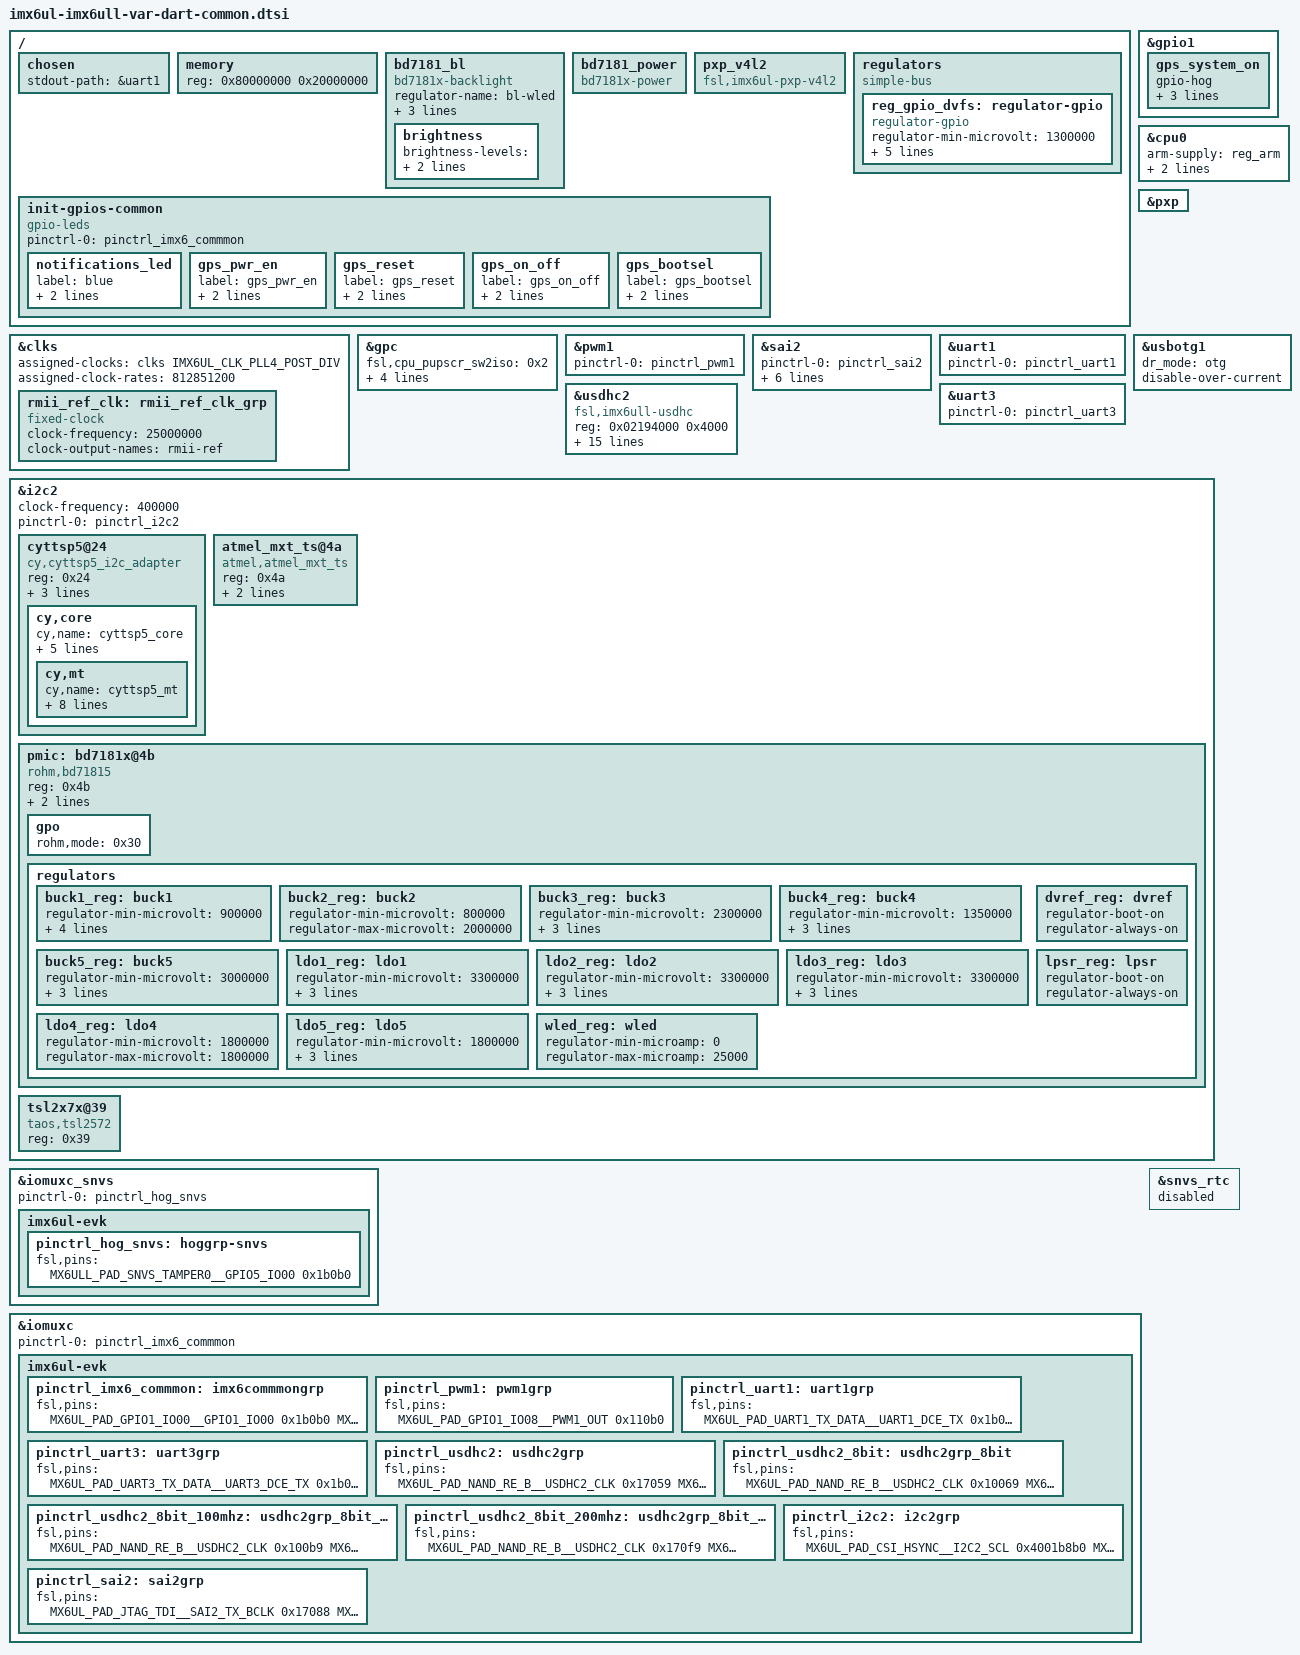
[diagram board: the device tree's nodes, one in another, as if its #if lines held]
/*
 * Copyright (C) 2015 Freescale Semiconductor, Inc.
 *
 * Copyright (C) 2015-2017 Variscite Ltd. - http://www.variscite.com
 *
 * This program is free software; you can redistribute it and/or modify
 * it under the terms of the GNU General Public License version 2 as
 * published by the Free Software Foundation.
 */
/* #define WIFI */
/* #define EMMC */
/* #define  NAND  */
 
/ {
	chosen {
		stdout-path = &uart1;
	};

	memory {
		reg = <0x80000000 0x20000000>;
	};

	bd7181_bl {
		compatible = "bd7181x-backlight";
		regulator-name = "bl-wled";
		regulator-boot-on;
		regulator-supply = "backlight";
		backlight-supply = <&wled_reg>;

		brightness {
			brightness-levels = <0 10 20 30 50 70 100 200 300 500 700 1000 2000 3000 4000 5000 6000 7000 8000 9000 
								10000 11000 12000 13000 14000 15000 16000 17000 18000 19000 20000 21000 22000 23000 24000 25000>;
			default-brightness-level = <15>;
		};
	};

	bd7181_power {
		compatible = "bd7181x-power";
		status = "okay";
	};

	pxp_v4l2 {
		compatible = "fsl,imx6ul-pxp-v4l2", "fsl,imx6sx-pxp-v4l2", "fsl,imx6sl-pxp-v4l2";
		status = "okay";
	};

	
	regulators {
		compatible = "simple-bus";
		#address-cells = <1>;
		#size-cells = <0>;
		
		reg_gpio_dvfs: regulator-gpio {
			compatible = "regulator-gpio";
			regulator-min-microvolt = <1300000>;
			regulator-max-microvolt = <1400000>;
			regulator-name = "gpio_dvfs";
			regulator-type = "voltage";
			gpios = <&gpio4 13 GPIO_ACTIVE_HIGH>;
			states = <1300000 0x1 1400000 0x0>;
		};
	};

	init-gpios-common {
		compatible = "gpio-leds";
		pinctrl-names = "default";
		pinctrl-0 = <&pinctrl_imx6_commmon>;

		notifications_led {
			label = "blue";
			gpios = <&gpio1 7 GPIO_ACTIVE_HIGH>;
			default-state = "off";
		};

		gps_pwr_en {
			label = "gps_pwr_en";
			gpios = <&gpio2 3 GPIO_ACTIVE_HIGH>;
			default-state = "off";
		};

		gps_reset {
			label = "gps_reset";
			gpios = <&gpio1 18 GPIO_ACTIVE_HIGH>;
			default-state = "off";
		};

		gps_on_off {
			label = "gps_on_off";
			gpios = <&gpio1 26 GPIO_ACTIVE_HIGH>;
			default-state = "off";
		};

		gps_bootsel {
			label = "gps_bootsel";
			gpios = <&gpio1 19 GPIO_ACTIVE_HIGH>;
			default-state = "off";
		};

	};

};

&gpio1 {
	gps_system_on {
		gpio-hog;
        gpios = <27 GPIO_ACTIVE_LOW>;
        input;
        line-name = "gps_system_on";
	};
};

&cpu0 {
	arm-supply = <&reg_arm>;
	soc-supply = <&reg_soc>;
	dc-supply = <&reg_gpio_dvfs>;
};

&clks {
	/* ref_clk for micrel ethernet phy */
	rmii_ref_clk: rmii_ref_clk_grp {
		compatible = "fixed-clock";
		#clock-cells = <0>;
		clock-frequency = <25000000>;
		clock-output-names = "rmii-ref";
	};
};

&clks {
	assigned-clocks = <&clks IMX6UL_CLK_PLL4_POST_DIV>;
	assigned-clock-rates = <812851200>;
};

&gpc {
	fsl,cpu_pupscr_sw2iso = <0x2>;
	fsl,cpu_pupscr_sw = <0x1>;
	fsl,cpu_pdnscr_iso2sw = <0x1>;
	fsl,cpu_pdnscr_iso = <0x1>;
	fsl,ldo-bypass = <0>; /* DCDC, ldo-enable */
};

&pwm1 {
	pinctrl-names = "default";
	pinctrl-0 = <&pinctrl_pwm1>;
	status = "okay";
};

&pxp {
	status = "okay";
};

&sai2 {
	pinctrl-names = "default";
	pinctrl-0 = <&pinctrl_sai2>;
	assigned-clocks = <&clks IMX6UL_CLK_SAI2_SEL>,
                      <&clks IMX6UL_CLK_PLL4_AUDIO_DIV>,
                      <&clks IMX6UL_CLK_SAI2>;
	assigned-clock-rates = <0>, <786432000>, <12288000>;
	assigned-clock-parents = <&clks IMX6UL_CLK_PLL4_AUDIO_DIV>;
	status = "okay";
};

/* Console UART */
&uart1 {
	pinctrl-names = "default";
	pinctrl-0 = <&pinctrl_uart1>;
	status = "okay";
};

/* ttymxc2 UART [GPS]*/
&uart3 {
	pinctrl-names = "default";
	pinctrl-0 = <&pinctrl_uart3>;
	status = "okay";
};

&usbotg1 {
	dr_mode = "otg";
	disable-over-current;
	status = "okay";
};

&usdhc2 {
	compatible = "fsl,imx6ull-usdhc", "fsl,imx6sx-usdhc";
	reg = <0x02194000 0x4000>;
	interrupts = <GIC_SPI 23 IRQ_TYPE_LEVEL_HIGH>;
	clocks = <&clks IMX6UL_CLK_USDHC2>,
		 <&clks IMX6UL_CLK_USDHC2>,
		 <&clks IMX6UL_CLK_USDHC2>;
	clock-names = "ipg", "ahb", "per";
	assigned-clocks = <&clks IMX6UL_CLK_USDHC2_SEL>, <&clks IMX6UL_CLK_USDHC2>;
	assigned-clock-parents = <&clks IMX6UL_CLK_PLL2_PFD2>;
	assigned-clock-rates = <0>, <132000000>;
	bus-width = <8>;
	fsl,tuning-step= <2>;
	pinctrl-names = "default", "state_100mhz", "state_200mhz";
	pinctrl-0 = <&pinctrl_usdhc2_8bit>;
	pinctrl-1 = <&pinctrl_usdhc2_8bit_100mhz>;
	pinctrl-2 = <&pinctrl_usdhc2_8bit_200mhz>;
	non-removable;
	status = "okay";
};

/* NOT USED. CHECK
&i2c1 {
	clock-frequency = <400000>;
	pinctrl-names = "default";
	pinctrl-0 = <&pinctrl_i2c1>;
	status = "okay";

};
*/

#ifdef WIFI
&i2c2 {
	clock-frequency = <400000>;
	pinctrl-names = "default";
	pinctrl-0 = <&pinctrl_i2c2>;
	status = "okay";

	cyttsp5@24 {
		compatible = "cy,cyttsp5_i2c_adapter";
		reg = <0x24>;
		interrupt-parent = <&gpio2>;
		interrupts = <2 IRQ_TYPE_EDGE_FALLING>;
		cy,adapter_id = "cyttsp5_i2c_adapter";

		cy,core {
			cy,name = "cyttsp5_core";

			cy,irq_gpio = <34>;
			cy,rst_gpio = <39>;
			cy,hid_desc_register = <1>;
			/* CY_CORE_FLAG_RESTORE_PARAMETERS */
			cy,flags = <4>;
			/* CY_CORE_EWG_NONE */
			cy,easy_wakeup_gesture = <0>;

			cy,mt {
				cy,name = "cyttsp5_mt";

				cy,inp_dev_name = "cyttsp5_mt";
				cy,flags = <0>;
				cy,abs =
					/* ABS_MT_POSITION_X, CY_ABS_MIN_X, CY_ABS_MAX_X, 0, 0 */
					<0x35 0 480 0 0
					/* ABS_MT_POSITION_Y, CY_ABS_MIN_Y, CY_ABS_MAX_Y, 0, 0 */
					0x36 0 900 0 0
					/* ABS_MT_PRESSURE, CY_ABS_MIN_P, CY_ABS_MAX_P, 0, 0 */
					0x3a 0 255 0 0
					/* CY_IGNORE_VALUE, CY_ABS_MIN_W, CY_ABS_MAX_W, 0, 0 */
					0xffff 0 255 0 0
					/* ABS_MT_TRACKING_ID, CY_ABS_MIN_T, CY_ABS_MAX_T, 0, 0 */
					0x39 0 15 0 0
					/* ABS_MT_TOUCH_MAJOR, 0, 255, 0, 0 */
					0x30 0 255 0 0
					/* ABS_MT_TOUCH_MINOR, 0, 255, 0, 0 */
					0x31 0 255 0 0
					/* ABS_MT_ORIENTATION, -127, 127, 0, 0 */
					0x34 0xffffff81 127 0 0
					/* ABS_MT_TOOL_TYPE, 0, MT_TOOL_MAX, 0, 0 */
					0x37 0 1 0 0
					/* ABS_DISTANCE, 0, 255, 0, 0 */
					0x19 0 255 0 0>;

				cy,x_max = <480>;
				cy,y_max = <800>;
				cy,p_max = <255>;
				cy,slots_max = <32>;

			};
		};
	};

	atmel_mxt_ts@4a {
		compatible = "atmel,atmel_mxt_ts";
		reg = <0x4a>;				
		interrupt-parent = <&gpio2>;
		interrupts = <2 IRQ_TYPE_LEVEL_LOW>;		
 	};   

	pmic: bd7181x@4b {
		compatible = "rohm,bd71815";
		reg = <0x4b>;
		gpio_intr = <&gpio2 12 IRQ_TYPE_EDGE_FALLING>;
		irq_base = <0>;

		gpo {
			rohm,mode = <0x30>;	/* 0b0011_0000 all gpos with cmos output mode */
		};

		regulators {
                        buck1_reg: buck1 {
                                regulator-min-microvolt = <900000>;
                                regulator-max-microvolt = <1400000>;
                                regulator-boot-on;
                                regulator-always-on;
                                regulator-ramp-delay = <6250>;
                        };

                        buck2_reg: buck2 {
                                regulator-min-microvolt = <800000>;
                                regulator-max-microvolt = <2000000>;
                        };

                        buck3_reg: buck3 {
                                regulator-min-microvolt = <2300000>;
                                regulator-max-microvolt = <2300000>;
                                regulator-boot-on;
                                regulator-always-on;
                        };

                        buck4_reg: buck4 {
                                regulator-min-microvolt = <1350000>;
                                regulator-max-microvolt = <1350000>;
                                regulator-boot-on;
                                regulator-always-on;
                        };

                        buck5_reg: buck5 {
                                regulator-min-microvolt = <3000000>;
                                regulator-max-microvolt = <3000000>;
                                regulator-boot-on;
                                regulator-always-on;
                        };

                        ldo1_reg: ldo1 {
                                regulator-min-microvolt = <3300000>;
                                regulator-max-microvolt = <3300000>;
                                regulator-boot-on;
                                regulator-always-on;
                        };

                        ldo2_reg: ldo2 {
                                regulator-min-microvolt = <3300000>;
                                regulator-max-microvolt = <3300000>;
                                regulator-boot-on;
                                regulator-always-on;
                        };

                        ldo3_reg: ldo3 {
                                regulator-min-microvolt = <3300000>;
                                regulator-max-microvolt = <3300000>;
                                regulator-boot-on;
                                regulator-always-on;
                        };

                        ldo4_reg: ldo4 {
                                regulator-min-microvolt = <1800000>;
                                regulator-max-microvolt = <1800000>;
                        };

                        ldo5_reg: ldo5 {
                                regulator-min-microvolt = <1800000>;
                                regulator-max-microvolt = <1800000>;
                                regulator-boot-on;
                                regulator-always-on;
                        };

                        dvref_reg: dvref {
                                regulator-boot-on;
                                regulator-always-on;
                        };

                        lpsr_reg: lpsr {
                                regulator-boot-on;
                                regulator-always-on;
                        };

                        wled_reg: wled {
                                regulator-min-microamp = <0>;
                                regulator-max-microamp = <25000>;
                                /*regulator-boot-on;*/
                        };

		};

	};

	tsl2x7x@39 {
        	compatible = "taos,tsl2572";
        	reg = <0x39>;
    };
};
#endif


&iomuxc_snvs {
	pinctrl-names = "default_snvs";
	pinctrl-0 = <&pinctrl_hog_snvs>;
	imx6ul-evk {
		pinctrl_hog_snvs: hoggrp-snvs {
			fsl,pins = <
				MX6ULL_PAD_SNVS_TAMPER0__GPIO5_IO00	0x1b0b0
			>;
		};
	};
};

&iomuxc {
	pinctrl-names = "default";
	pinctrl-0 = <&pinctrl_imx6_commmon>;
	imx6ul-evk {
		pinctrl_imx6_commmon: imx6commmongrp {
			fsl,pins = <
				/* MX6UL_PAD_CSI_HSYNC__GPIO4_IO20		0x1b0b0	User LED - Check */
				MX6UL_PAD_GPIO1_IO00__GPIO1_IO00		0x1b0b0   /* necessary for USB-ID --- old pin cfg -> 0x17059 */
				MX6UL_PAD_GPIO1_IO07__GPIO1_IO07		0x1b0b0   /* Notification Led */
				/* MX6UL_PAD_GPIO1_IO06__ENET2_MDIO	0x1b0b0 Need to Check */
				/*-------------------------------GPS-----------------------------------*/
				MX6UL_PAD_UART3_RTS_B__GPIO1_IO27		0x130b0 /* GPS_SYSTEM_ON (INPUT) Pull down!! */
				MX6UL_PAD_UART3_CTS_B__GPIO1_IO26		0x1b0b0 /* GPS_ON_OFF */
				MX6UL_PAD_UART1_CTS_B__GPIO1_IO18		0x1b0b0 /* GPS_RESET */
				MX6UL_PAD_ENET1_TX_DATA0__GPIO2_IO03	0x1b0b0 /* GPS_PWR_EN */
				MX6UL_PAD_UART1_RTS_B__GPIO1_IO19		0x1b0b0 /* GPS_BOOTSEL */
				/*-------------------------------PCAP----------------------------------*/
				MX6UL_PAD_ENET1_RX_ER__GPIO2_IO07		0x1b0b0 /* PCAP_RESET */
				MX6UL_PAD_ENET1_RX_EN__GPIO2_IO02		0x1b0b0 /* PCAP_INT */					
				/*---------------------------------------------------------------------*/
				/*MX6UL_PAD_LCD_DATA17__GPIO3_IO22		0x40000000 Sample to get feedback from grpio sysfs*/
				/*-------------------------------BD7181x--------------------------------*/
				MX6UL_PAD_ENET2_TX_DATA1__GPIO2_IO12    0x1b0b0 /* PMICIO.INT_OUT */
			>;			
		};

		pinctrl_pwm1: pwm1grp {
			fsl,pins = <
				MX6UL_PAD_GPIO1_IO08__PWM1_OUT		0x110b0
			>;
		};

		pinctrl_uart1: uart1grp { /* DEBUG */
			fsl,pins = <
				MX6UL_PAD_UART1_TX_DATA__UART1_DCE_TX	0x1b0b1
				MX6UL_PAD_UART1_RX_DATA__UART1_DCE_RX	0x1b0b1
			>;
		};

		pinctrl_uart3: uart3grp { /* GPS */
			fsl,pins = <
				MX6UL_PAD_UART3_TX_DATA__UART3_DCE_TX	0x1b0b1
				MX6UL_PAD_UART3_RX_DATA__UART3_DCE_RX	0x1b0b1
			>;
		};

		pinctrl_usdhc2: usdhc2grp {
			fsl,pins = <
				MX6UL_PAD_NAND_RE_B__USDHC2_CLK		0x17059
				MX6UL_PAD_NAND_WE_B__USDHC2_CMD		0x17059
				MX6UL_PAD_NAND_DATA00__USDHC2_DATA0	0x17059
				MX6UL_PAD_NAND_DATA01__USDHC2_DATA1	0x17059
				MX6UL_PAD_NAND_DATA02__USDHC2_DATA2	0x17059
				MX6UL_PAD_NAND_DATA03__USDHC2_DATA3	0x17059
			>;
		};

		pinctrl_usdhc2_8bit: usdhc2grp_8bit {
			fsl,pins = <
				MX6UL_PAD_NAND_RE_B__USDHC2_CLK     0x10069
				MX6UL_PAD_NAND_WE_B__USDHC2_CMD     0x17059
				MX6UL_PAD_NAND_DATA00__USDHC2_DATA0 0x17059
				MX6UL_PAD_NAND_DATA01__USDHC2_DATA1 0x17059
				MX6UL_PAD_NAND_DATA02__USDHC2_DATA2 0x17059
				MX6UL_PAD_NAND_DATA03__USDHC2_DATA3 0x17059
				MX6UL_PAD_NAND_DATA04__USDHC2_DATA4 0x17059
				MX6UL_PAD_NAND_DATA05__USDHC2_DATA5 0x17059
				MX6UL_PAD_NAND_DATA06__USDHC2_DATA6 0x17059
				MX6UL_PAD_NAND_DATA07__USDHC2_DATA7 0x17059
			>;
		};

		pinctrl_usdhc2_8bit_100mhz: usdhc2grp_8bit_100mhz {
			fsl,pins = <
				MX6UL_PAD_NAND_RE_B__USDHC2_CLK     0x100b9
				MX6UL_PAD_NAND_WE_B__USDHC2_CMD     0x170b9
				MX6UL_PAD_NAND_DATA00__USDHC2_DATA0 0x170b9
				MX6UL_PAD_NAND_DATA01__USDHC2_DATA1 0x170b9
				MX6UL_PAD_NAND_DATA02__USDHC2_DATA2 0x170b9
				MX6UL_PAD_NAND_DATA03__USDHC2_DATA3 0x170b9
				MX6UL_PAD_NAND_DATA04__USDHC2_DATA4 0x170b9
				MX6UL_PAD_NAND_DATA05__USDHC2_DATA5 0x170b9
				MX6UL_PAD_NAND_DATA06__USDHC2_DATA6 0x170b9
				MX6UL_PAD_NAND_DATA07__USDHC2_DATA7 0x170b9
			>;
		};

		pinctrl_usdhc2_8bit_200mhz: usdhc2grp_8bit_200mhz {
			fsl,pins = <
				MX6UL_PAD_NAND_RE_B__USDHC2_CLK     0x170f9
				MX6UL_PAD_NAND_WE_B__USDHC2_CMD     0x170e1
				MX6UL_PAD_NAND_DATA00__USDHC2_DATA0 0x170e1
				MX6UL_PAD_NAND_DATA01__USDHC2_DATA1 0x170e1
				MX6UL_PAD_NAND_DATA02__USDHC2_DATA2 0x170e1
				MX6UL_PAD_NAND_DATA03__USDHC2_DATA3 0x170e1
				MX6UL_PAD_NAND_DATA04__USDHC2_DATA4 0x170e1
				MX6UL_PAD_NAND_DATA05__USDHC2_DATA5 0x170e1
				MX6UL_PAD_NAND_DATA06__USDHC2_DATA6 0x170e1
				MX6UL_PAD_NAND_DATA07__USDHC2_DATA7 0x170e1
			>;
		};

#ifdef WIFI
        pinctrl_i2c2: i2c2grp {
            fsl,pins = <
                MX6UL_PAD_CSI_HSYNC__I2C2_SCL   0x4001b8b0
                MX6UL_PAD_CSI_VSYNC__I2C2_SDA   0x4001b8b0
            >;
        };
#endif

		pinctrl_sai2: sai2grp {
			fsl,pins = <
				MX6UL_PAD_JTAG_TDI__SAI2_TX_BCLK	0x17088
				MX6UL_PAD_JTAG_TDO__SAI2_TX_SYNC	0x17088
				MX6UL_PAD_JTAG_TRST_B__SAI2_TX_DATA	0x11088
			>;
		};
	};
};

&snvs_rtc {
       status = "disabled";
};

